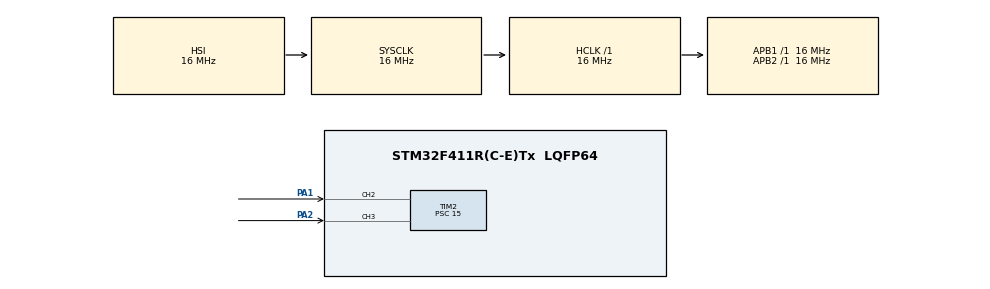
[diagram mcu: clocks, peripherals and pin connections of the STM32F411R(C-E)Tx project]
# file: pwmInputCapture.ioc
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Mcu.Family=STM32F4
Mcu.Name=STM32F411R(C-E)Tx
Mcu.Package=LQFP64
NVIC.PriorityGroup=NVIC_PRIORITYGROUP_4
PA1.Signal=S_TIM2_CH2
PA2.Signal=S_TIM2_CH3
ProjectManager.HeapSize=0x200
ProjectManager.StackSize=0x400
ProjectManager.TargetToolchain=STM32CubeIDE
RCC.AHBFreq_Value=16000000
RCC.APB1Freq_Value=16000000
RCC.APB2Freq_Value=16000000
RCC.CortexFreq_Value=16000000
RCC.HSE_VALUE=25000000
RCC.HSI_VALUE=16000000
RCC.LSE_VALUE=32768
RCC.SYSCLKFreq_VALUE=16000000
RCC.VCOOutputFreq_Value=192000000
SH.S_TIM2_CH2.0=TIM2_CH2,TriggerSource_TI2FP2
SH.S_TIM2_CH2.1=TIM2_CH2,Input_Capture2_from_TI2
SH.S_TIM2_CH3.0=TIM2_CH3,Input_Capture3_from_TI3
TIM2.Channel-Input_Capture2_from_TI2=TIM_CHANNEL_2
TIM2.Channel-Input_Capture3_from_TI3=TIM_CHANNEL_3
TIM2.ICPolarity_CH3=TIM_INPUTCHANNELPOLARITY_FALLING
TIM2.Period=65535
TIM2.Prescaler=15
VP_TIM2_VS_ControllerModeReset.Mode=Reset Mode
board=custom

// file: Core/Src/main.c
/* USER CODE BEGIN Header */
/**
  ******************************************************************************
  * @file           : main.c
  * @brief          : Main program body
  ******************************************************************************
  * @attention
  *
  * <h2><center>&copy; Copyright (c) 2020 STMicroelectronics.
  * All rights reserved.</center></h2>
  *
  * This software component is licensed by ST under BSD 3-Clause license,
  * the "License"; You may not use this file except in compliance with the
  * License. You may obtain a copy of the License at:
  *                        opensource.org/licenses/BSD-3-Clause
  *
  ******************************************************************************
  */
/* USER CODE END Header */
#include "main.h"

TIM_HandleTypeDef htim2;

void SystemClock_Config(void);
static void MX_GPIO_Init(void);
static void MX_TIM2_Init(void);

/* USER CODE BEGIN 0 */

uint32_t IC_Val1 = 0;
uint32_t IC_Val2 = 0;
uint32_t Frequency = 0;
uint32_t Duty_Cycle = 0;

// write the input capture callback

void HAL_TIM_IC_CaptureCallback(TIM_HandleTypeDef *htim)
{
	if (htim->Channel == HAL_TIM_ACTIVE_CHANNEL_2)  // rising edge interrupt
	{
		// read captured value
		IC_Val1 = HAL_TIM_ReadCapturedValue(htim, TIM_CHANNEL_2);  // first value

		if (IC_Val1 != 0)  // if the value is not 0
		{
			// read second value
			IC_Val2 = HAL_TIM_ReadCapturedValue(htim, TIM_CHANNEL_3); // falling edge value

			// calculate Duty cycle

			Duty_Cycle = (IC_Val2*100/IC_Val1);

			// calculate frequency

			Frequency = (2*HAL_RCC_GetPCLK1Freq()/IC_Val1);
			// As my timer2 clock is 2X the PCLK1 CLOCK that's why X2.
		}

		else
		{
			Duty_Cycle = 0;
			Frequency = 0;
		}
	}
}
/* USER CODE END 0 */

int main(void)
{

  /* MCU Configuration--------------------------------------------------------*/

  /* Reset of all peripherals, Initializes the Flash interface and the Systick. */
  HAL_Init();

  /* Configure the system clock */
  SystemClock_Config();

  /* Initialize all configured peripherals */
  MX_GPIO_Init();
  MX_TIM2_Init();
  /* USER CODE BEGIN 2 */
  HAL_TIM_IC_Start_IT(&htim2, TIM_CHANNEL_2);
  HAL_TIM_IC_Start_IT(&htim2, TIM_CHANNEL_3);

  /* USER CODE END 2 */

  /* Infinite loop */
  /* USER CODE BEGIN WHILE */
  while (1)
  {
	  HAL_Delay(500);
    /* USER CODE END WHILE */

  }
}

void SystemClock_Config(void)
{
  RCC_OscInitTypeDef RCC_OscInitStruct = {0};
  RCC_ClkInitTypeDef RCC_ClkInitStruct = {0};

  /** Configure the main internal regulator output voltage
  */
  __HAL_RCC_PWR_CLK_ENABLE();
  __HAL_PWR_VOLTAGESCALING_CONFIG(PWR_REGULATOR_VOLTAGE_SCALE1);
  /** Initializes the RCC Oscillators according to the specified parameters
  * in the RCC_OscInitTypeDef structure.
  */
  RCC_OscInitStruct.OscillatorType = RCC_OSCILLATORTYPE_HSI;
  RCC_OscInitStruct.HSIState = RCC_HSI_ON;
  RCC_OscInitStruct.HSICalibrationValue = RCC_HSICALIBRATION_DEFAULT;
  RCC_OscInitStruct.PLL.PLLState = RCC_PLL_NONE;
  if (HAL_RCC_OscConfig(&RCC_OscInitStruct) != HAL_OK)
  {
    Error_Handler();
  }
  /** Initializes the CPU, AHB and APB buses clocks
  */
  RCC_ClkInitStruct.ClockType = RCC_CLOCKTYPE_HCLK|RCC_CLOCKTYPE_SYSCLK
                              |RCC_CLOCKTYPE_PCLK1|RCC_CLOCKTYPE_PCLK2;
  RCC_ClkInitStruct.SYSCLKSource = RCC_SYSCLKSOURCE_HSI;
  RCC_ClkInitStruct.AHBCLKDivider = RCC_SYSCLK_DIV1;
  RCC_ClkInitStruct.APB1CLKDivider = RCC_HCLK_DIV1;
  RCC_ClkInitStruct.APB2CLKDivider = RCC_HCLK_DIV1;

  if (HAL_RCC_ClockConfig(&RCC_ClkInitStruct, FLASH_LATENCY_0) != HAL_OK)
  {
    Error_Handler();
  }
}

static void MX_TIM2_Init(void)
{

  TIM_SlaveConfigTypeDef sSlaveConfig = {0};
  TIM_MasterConfigTypeDef sMasterConfig = {0};
  TIM_IC_InitTypeDef sConfigIC = {0};

  htim2.Instance = TIM2;
  htim2.Init.Prescaler = 15;
  htim2.Init.CounterMode = TIM_COUNTERMODE_UP;
  htim2.Init.Period = 65535;
  htim2.Init.ClockDivision = TIM_CLOCKDIVISION_DIV1;
  htim2.Init.AutoReloadPreload = TIM_AUTORELOAD_PRELOAD_DISABLE;
  if (HAL_TIM_Base_Init(&htim2) != HAL_OK)
  {
    Error_Handler();
  }
  if (HAL_TIM_IC_Init(&htim2) != HAL_OK)
  {
    Error_Handler();
  }
  sSlaveConfig.SlaveMode = TIM_SLAVEMODE_RESET;
  sSlaveConfig.InputTrigger = TIM_TS_TI2FP2;
  sSlaveConfig.TriggerPolarity = TIM_INPUTCHANNELPOLARITY_RISING;
  sSlaveConfig.TriggerFilter = 0;
  if (HAL_TIM_SlaveConfigSynchro(&htim2, &sSlaveConfig) != HAL_OK)
  {
    Error_Handler();
  }
  sMasterConfig.MasterOutputTrigger = TIM_TRGO_RESET;
  sMasterConfig.MasterSlaveMode = TIM_MASTERSLAVEMODE_DISABLE;
  if (HAL_TIMEx_MasterConfigSynchronization(&htim2, &sMasterConfig) != HAL_OK)
  {
    Error_Handler();
  }
  sConfigIC.ICPolarity = TIM_INPUTCHANNELPOLARITY_RISING;
  sConfigIC.ICSelection = TIM_ICSELECTION_DIRECTTI;
  sConfigIC.ICPrescaler = TIM_ICPSC_DIV1;
  sConfigIC.ICFilter = 0;
  if (HAL_TIM_IC_ConfigChannel(&htim2, &sConfigIC, TIM_CHANNEL_2) != HAL_OK)
  {
    Error_Handler();
  }
  sConfigIC.ICPolarity = TIM_INPUTCHANNELPOLARITY_FALLING;
  if (HAL_TIM_IC_ConfigChannel(&htim2, &sConfigIC, TIM_CHANNEL_3) != HAL_OK)
  {
    Error_Handler();
  }

}

static void MX_GPIO_Init(void)
{

  /* GPIO Ports Clock Enable */
  __HAL_RCC_GPIOA_CLK_ENABLE();

}

void Error_Handler(void)
{
}

/************************ (C) COPYRIGHT STMicroelectronics *****END OF FILE****/
